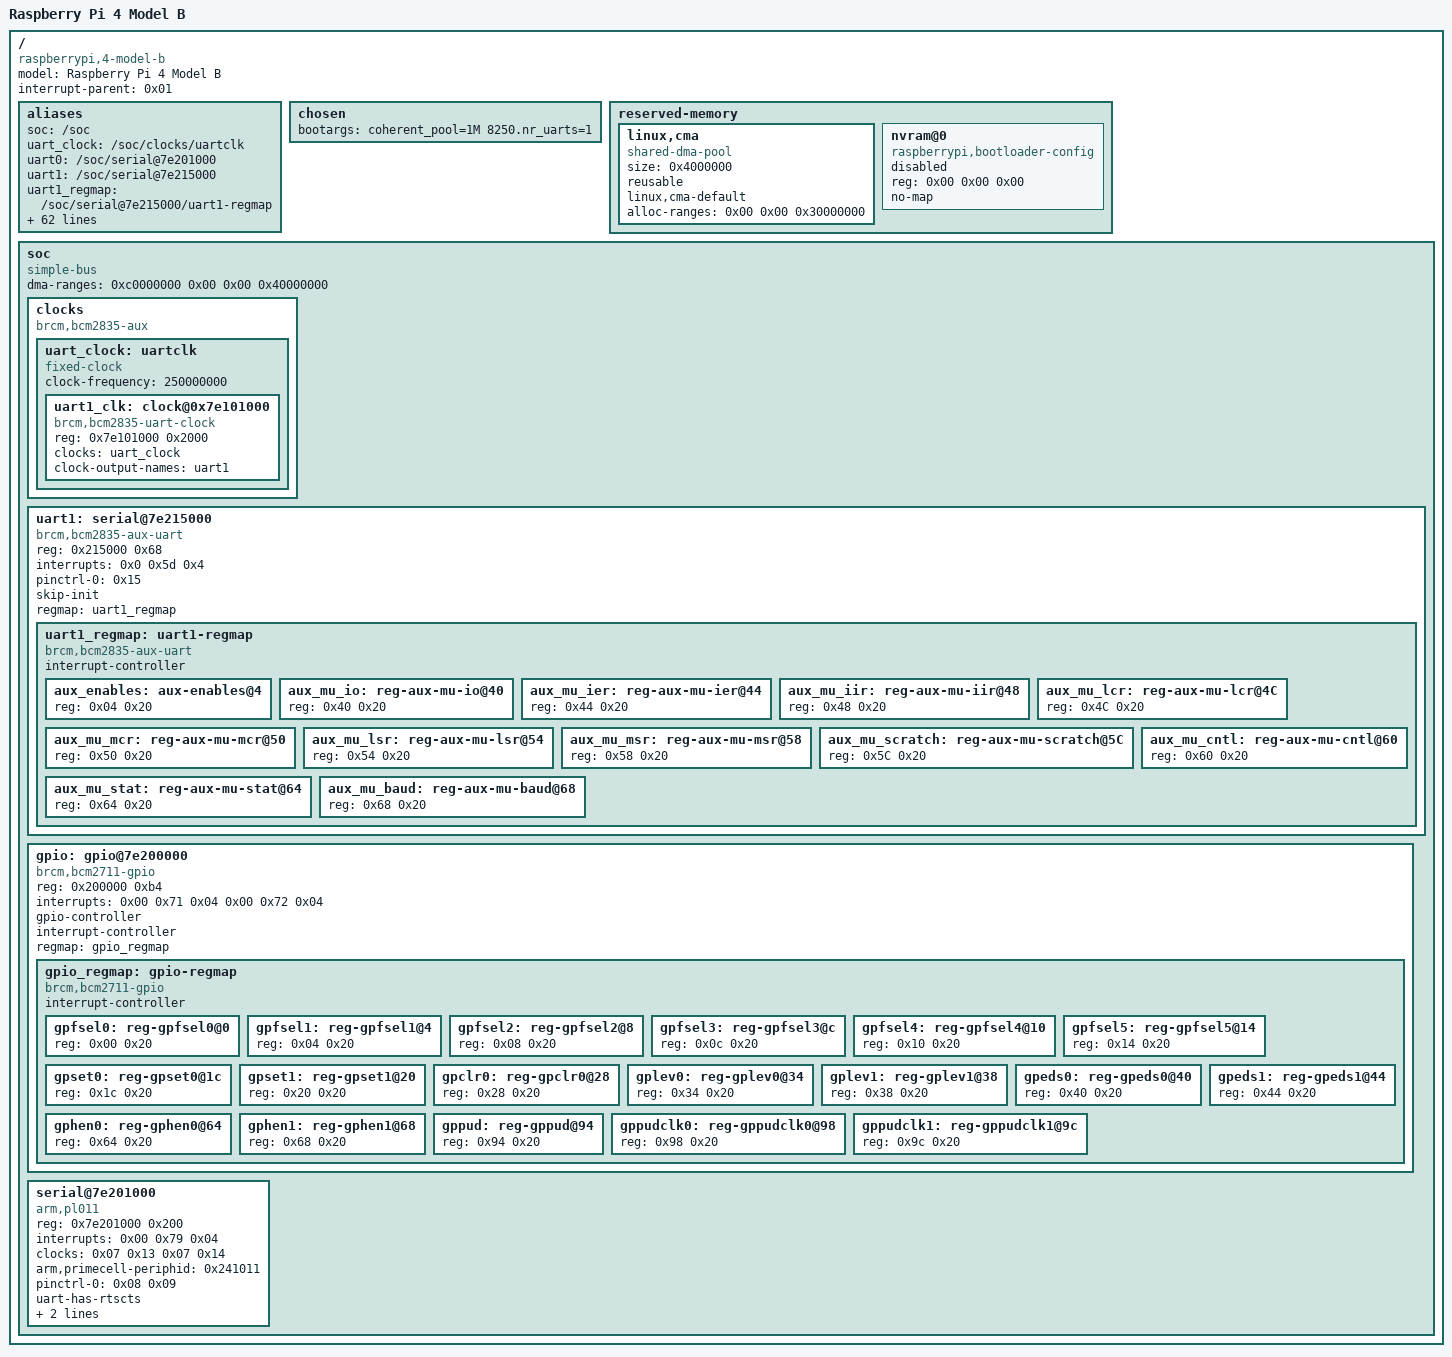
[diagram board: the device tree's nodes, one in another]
/dts-v1/;

/memreserve/	0x0000000000000000 0x0000000000001000;
/ {
	compatible = "raspberrypi,4-model-b\0brcm,bcm2711";
	model = "Raspberry Pi 4 Model B";
	#address-cells = <0x02>;
	#size-cells = <0x01>;
	interrupt-parent = <0x01>;

	aliases {
		soc = "/soc";
		uart_clock = "/soc/clocks/uartclk";
		uart0 = "/soc/serial@7e201000";
		uart1 = "/soc/serial@7e215000";
		uart1_regmap = "/soc/serial@7e215000/uart1-regmap";
		aux_enables = "/soc/serial@7e215000/uart1-regmap/aux-enables@4";
		aux_mu_io = "/soc/serial@7e215000/uart1-regmap/reg-aux-mu-io@40";
		aux_mu_ier = "/soc/serial@7e215000/uart1-regmap/reg-aux-mu-ier@44";
		aux_mu_iir = "/soc/serial@7e215000/uart1-regmap/reg-aux-mu-iir@48";
		aux_mu_lcr = "/soc/serial@7e215000/uart1-regmap/reg-aux-mu-lcr@4C";
		aux_mu_mcr = "/soc/serial@7e215000/uart1-regmap/reg-aux-mu-mcr@50";
		aux_mu_lsr = "/soc/serial@7e215000/uart1-regmap/reg-aux-mu-lsr@54";
		aux_mu_msr = "/soc/serial@7e215000/uart1-regmap/reg-aux-mu-msr@58";
		aux_mu_scratch = "/soc/serial@7e215000/uart1-regmap/reg-aux-mu-scratch@5C";
		aux_mu_cntl = "/soc/serial@7e215000/uart1-regmap/reg-aux-mu-cntl@60";
		aux_mu_stat = "/soc/serial@7e215000/uart1-regmap/reg-aux-mu-stat@64";
		aux_mu_baud = "/soc/serial@7e215000/uart1-regmap/reg-aux-mu-baud@68";
		gpio = "/soc/gpio@7e200000";
		gpio_regmap = "/soc/gpio@7e200000/gpio-regmap";
		gpfsel0 =  "/soc/gpio@7e200000/gpio-regmap/reg-gpfsel0@0"; 
		gpfsel1 = "/soc/gpio@7e200000/gpio-regmap/reg-gpfsel1@4";
		gpfsel2 = "/soc/gpio@7e200000/gpio-regmap/reg-gpfsel2@8";
		gpfsel3 = "/soc/gpio@7e200000/gpio-regmap/reg-gpfsel3@c"; 
		gpfsel4 = "/soc/gpio@7e200000/gpio-regmap/reg-gpfsel4@10";
		gpfsel5 = "/soc/gpio@7e200000/gpio-regmap/reg-gpfsel5@14";
		gpset0 = "/soc/gpio@7e200000/gpio-regmap/reg-gpset0@1c";
		gpset1 = "/soc/gpio@7e200000/gpio-regmap/reg-gpset1@20";
		gpclr0 = "/soc/gpio@7e200000/gpio-regmap/reg-gpclr0@28";
		gplev0 = "/soc/gpio@7e200000/gpio-regmap/reg-gplev0@34";
		gplev1 = "/soc/gpio@7e200000/gpio-regmap/reg-gplev1@38";
		gpeds0 = "/soc/gpio@7e200000/gpio-regmap/reg-gpeds0@40";
		gpeds1 = "/soc/gpio@7e200000/gpio-regmap/reg-gpeds1@44";
		gphen0 = "/soc/gpio@7e200000/gpio-regmap/reg-gphen0@64";
		gphen1 = "/soc/gpio@7e200000/gpio-regmap/reg-gphen1@68";
		gppud = "/soc/gpio@7e200000/gpio-regmap/reg-gppud@94";
		gppudclk0 = "/soc/gpio@7e200000/gpio-regmap/reg-gppudclk0@98";
		gppudclk1 = "/soc/gpio@7e200000/gpio-regmap/reg-gppudclk1@9c";
	};

	chosen {
		bootargs = "coherent_pool=1M 8250.nr_uarts=1";
	};

	reserved-memory {
		#address-cells = <0x02>;
		#size-cells = <0x01>;
		ranges;
		phandle = <0x41>;

		linux,cma {
			compatible = "shared-dma-pool";
			size = <0x4000000>;
			reusable;
			linux,cma-default;
			alloc-ranges = <0x00 0x00 0x30000000>;
			phandle = <0x42>;
		};

		nvram@0 {
			compatible = "raspberrypi,bootloader-config\0nvmem-rmem";
			#address-cells = <0x01>;
			#size-cells = <0x01>;
			reg = <0x00 0x00 0x00>;
			no-map;
			status = "disabled";
			phandle = <0x43>;
		};
	};


	soc {
		compatible = "simple-bus";
		#address-cells = <0x01>;
		#size-cells = <0x01>;
		ranges = <0x7e000000 0x00 0xfe000000 0x1800000 0x7c000000 0x00 0xfc000000 0x2000000 0x40000000 0x00 0xff800000 0x800000>;
		dma-ranges = <0xc0000000 0x00 0x00 0x40000000>;
		phandle = <0x45>;

		clocks{
			compatible = "brcm,bcm2835-aux";
    		#clock-cells = <1>;

			uart_clock: uartclk {
				compatible = "fixed-clock";
				#clock-cells = <1>;
				clock-frequency = "250000000"; // Frecuencia del reloj en Hz 250000000

				// Propiedades específicas del UART1
				uart1_clk: clock@0x7e101000 {
					compatible = "brcm,bcm2835-uart-clock";
					reg = <0x7e101000 0x2000>; // Inserta el índice del registro de configuración del reloj del UART1
					clocks = <&uart_clock>;
					clock-output-names = "uart1";
				};
			};
		};


		uart1: serial@7e215000 {
			#address-cells = <1>;
            #size-cells = <2>;
			compatible = "brcm,bcm2835-aux-uart"; // indica el controlador o driver compatible con el dispositivo, en este caso del uart.
			reg = <0x215000 0x68>; // rango de direcciones disponibles, en este caso son las direcciones usadas para el uart1.
			interrupts = <0x0 0x5d 0x4>; //La sintaxis utilizada es <interrupt-controller-id> <interrupt-id> <interrupt-flag>
			/**
				<interrupt-controller-id>: 0x0. Esto indica el identificador del controlador de interrupciones al que está conectado el UART.
				<interrupt-id>: 0x5d. Este es el número de identificación de la interrupción específica del UART.
				<interrupt-flag>: 0x4. Indica el tipo de interrupción o su configuración adicional.
			*/
			status = "okay";
			pinctrl-names = "default";
			pinctrl-0 = <0x15>;
			skip-init;
			phandle = <0x31>;

			regmap = <&uart1_regmap>;

			uart1_regmap: uart1-regmap {
				compatible = "brcm,bcm2835-aux-uart";
				#address-cells = <1>;
				#size-cells = <1>;
				interrupt-controller;
				#interrupt-cells = <1>;

				aux_enables: aux-enables@4 {
					reg = <0x04 0x20>;
				};

				aux_mu_io: reg-aux-mu-io@40 {
					reg = <0x40 0x20>;
				};

				aux_mu_ier: reg-aux-mu-ier@44 {
					reg = <0x44 0x20>;
				};

				aux_mu_iir: reg-aux-mu-iir@48 {
					reg = <0x48 0x20>;
				};

				aux_mu_lcr: reg-aux-mu-lcr@4C {
					reg = <0x4C 0x20>;
				};

				aux_mu_mcr: reg-aux-mu-mcr@50 {
					reg = <0x50 0x20>;
				};

				aux_mu_lsr: reg-aux-mu-lsr@54 {
					reg = <0x54 0x20>;
				};

				aux_mu_msr: reg-aux-mu-msr@58 {
					reg = <0x58 0x20>;
				};

				aux_mu_scratch: reg-aux-mu-scratch@5C {
					reg = <0x5C 0x20>;
				};

				aux_mu_cntl: reg-aux-mu-cntl@60 {
					reg = <0x60 0x20>;
				};

				aux_mu_stat: reg-aux-mu-stat@64 {
					reg = <0x64 0x20>;
				};

				aux_mu_baud: reg-aux-mu-baud@68 {
					reg = <0x68 0x20>;
				};
			};
		};

		gpio: gpio@7e200000 {
			compatible = "brcm,bcm2711-gpio";
			reg = <0x200000 0xb4>;
			interrupts = <0x00 0x71 0x04 0x00 0x72 0x04>;
			/**
				<interrupt-controller-id>: 0x0. Esto indica el identificador del controlador de interrupciones al que está conectado el UART.
				<interrupt-id>: 0x71. Este es el número de identificación de la interrupción específica del UART.
				<interrupt-flag>: 0x04. Indica el tipo de interrupción o su configuración adicional.
			*/
			gpio-controller;
			#gpio-cells = <0x02>;
			interrupt-controller;
			#interrupt-cells = <0x02>;
			pinctrl-names = "default";
			// gpio-line-names = "ID_SDA\0ID_SCL\0SDA1\0SCL1\0GPIO_GCLK\0GPIO5\0GPIO6\0SPI_CE1_N\0SPI_CE0_N\0SPI_MISO\0SPI_MOSI\0SPI_SCLK\0GPIO12\0GPIO13\0TXD1\0RXD1\0GPIO16\0GPIO17\0GPIO18\0GPIO19\0GPIO20\0GPIO21\0GPIO22\0GPIO23\0GPIO24\0GPIO25\0GPIO26\0GPIO27\0RGMII_MDIO\0RGMIO_MDC\0CTS0\0RTS0\0TXD0\0RXD0\0SD1_CLK\0SD1_CMD\0SD1_DATA0\0SD1_DATA1\0SD1_DATA2\0SD1_DATA3\0PWM0_MISO\0PWM1_MOSI\0STATUS_LED_G_CLK\0SPIFLASH_CE_N\0SDA0\0SCL0\0RGMII_RXCLK\0RGMII_RXCTL\0RGMII_RXD0\0RGMII_RXD1\0RGMII_RXD2\0RGMII_RXD3\0RGMII_TXCLK\0RGMII_TXCTL\0RGMII_TXD0\0RGMII_TXD1\0RGMII_TXD2\0RGMII_TXD3";
			phandle = <0x0f>;

			regmap = <&gpio_regmap>;

			gpio_regmap: gpio-regmap {
				compatible = "brcm,bcm2711-gpio";
				#address-cells = <1>;
				#size-cells = <1>;
				interrupt-controller;
				#interrupt-cells = <1>;

				gpfsel0: reg-gpfsel0@0 {
					reg = <0x00 0x20>;
				};
		
				gpfsel1: reg-gpfsel1@4 {
					reg = <0x04 0x20>;
				};
		
				gpfsel2: reg-gpfsel2@8 {
					reg = <0x08 0x20>;
				};
		
				gpfsel3: reg-gpfsel3@c {
					reg = <0x0c 0x20>;
				};
		
				gpfsel4: reg-gpfsel4@10 {
					reg = <0x10 0x20>;
				};
		
				gpfsel5: reg-gpfsel5@14 {
					reg = <0x14 0x20>;
				};
		
				gpset0: reg-gpset0@1c {
					reg = <0x1c 0x20>;
				};
		
				gpset1: reg-gpset1@20 {
					reg = <0x20 0x20>;
				};
		
				gpclr0: reg-gpclr0@28 {
					reg = <0x28 0x20>;
				};
		
				gplev0: reg-gplev0@34 {
					reg = <0x34 0x20>;
				};
		
				gplev1: reg-gplev1@38 {
					reg = <0x38 0x20>;
				};
		
				gpeds0: reg-gpeds0@40 {
					reg = <0x40 0x20>;
				};
		
				gpeds1: reg-gpeds1@44 {
					reg = <0x44 0x20>;
				};
		
				gphen0: reg-gphen0@64 {
					reg = <0x64 0x20>;
				};
		
				gphen1: reg-gphen1@68 {
					reg = <0x68 0x20>;
				};
		
				gppud: reg-gppud@94 {
					reg = <0x94 0x20>;
				};
		
				gppudclk0: reg-gppudclk0@98 {
					reg = <0x98 0x20>;
				};
		
				gppudclk1: reg-gppudclk1@9c {
					reg = <0x9c 0x20>;
				};


			};
		};


		serial@7e201000 {
			compatible = "arm,pl011\0arm,primecell";
			reg = <0x7e201000 0x200>;
			interrupts = <0x00 0x79 0x04>;
			clocks = <0x07 0x13 0x07 0x14>;
			clock-names = "uartclk\0apb_pclk";
			arm,primecell-periphid = <0x241011>;
			pinctrl-names = "default";
			pinctrl-0 = <0x08 0x09>;
			uart-has-rtscts;
			status = "okay";
			cts-event-workaround;
			skip-init;
			phandle = <0x30>;

		};

	};


	// VER SI AÑADIR A OVERRIDES Y A SYMBOLS

	__overrides__ {
		uart1 = "\0\0\01status";
		gpio = "\0\0\01status";
	};


	__symbols__ {
		rmem = "/reserved-memory";
		soc = "/soc";
		uart1 = "/soc/serial@7e215000";
		gpio = "/soc/gpio@7e200000";
	};
};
